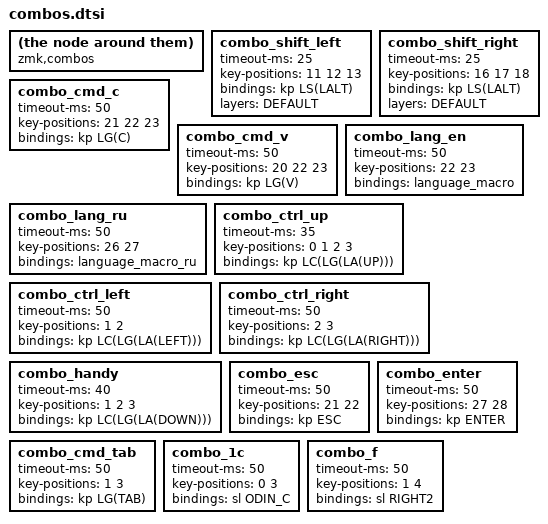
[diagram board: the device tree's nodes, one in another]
/*                KEY POSITIONS

╭────────────────────╮ ╭────────────────────╮
│  0   1   2   3   4 │ │  5   6   7   8   9 │
│ 10  11  12  13  14 │ │ 15  16  17  18  19 │
│ 20  21  22  23  24 │ │ 25  26  27  28  29 │
╰────────╮30  31  32 │ │ 33  34  35 ╭───────╯
         ╰───────────╯ ╰────────────╯       */

          
compatible = "zmk,combos";

// Shift
combo_shift_left { timeout-ms = <25>; key-positions = <11 13>; bindings = <&kp LSHIFT>; layers = <DEFAULT>; };
combo_shift_right { timeout-ms = <25>; key-positions = <16 18>; bindings = <&kp RSHIFT>; layers = <DEFAULT>; };
// Alt
combo_shift_left { timeout-ms = <25>; key-positions = <11 12>; bindings = <&kp LALT>; layers = <DEFAULT>; };
combo_shift_right { timeout-ms = <25>; key-positions = <17 18>; bindings = <&kp LALT>; layers = <DEFAULT>; };
// Alt+Shift
combo_shift_left { timeout-ms = <25>; key-positions = <11 12 13>; bindings = <&kp LS(LALT)>; layers = <DEFAULT>; };
combo_shift_right { timeout-ms = <25>; key-positions = <16 17 18>; bindings = <&kp LS(LALT)>; layers = <DEFAULT>; };

// Copy paste
combo_cmd_c { timeout-ms = <50>; key-positions = <21 22 23>; bindings = <&kp LG(C)>; };
// combo_cmd_x { timeout-ms = <50>; key-positions = <21 22>; bindings = <&kp LG(X)>; };
combo_cmd_v { timeout-ms = <50>; key-positions = <20 22 23>; bindings = <&kp LG(V)>; };

// Change language
combo_lang_en { timeout-ms = <50>; key-positions = <22 23>; bindings = <&language_macro>; };
combo_lang_ru { timeout-ms = <50>; key-positions = <26 27>; bindings = <&language_macro_ru>; };

// Mac Os navigation
combo_ctrl_up { timeout-ms = <35>; key-positions = <0 1 2 3>; bindings = <&kp LC(LG(LA(UP)))>; };
combo_ctrl_left { timeout-ms = <50>; key-positions = <1 2>; bindings = <&kp LC(LG(LA(LEFT)))>; };
combo_ctrl_right { timeout-ms = <50>; key-positions = <2 3>; bindings = <&kp LC(LG(LA(RIGHT)))>; };

// Handy push to talk
combo_handy { timeout-ms = <40>; key-positions = <1 2 3>; bindings = <&kp LC(LG(LA(DOWN)))>; };

// Esc and Enter
combo_esc { timeout-ms = <50>; key-positions = <21 22>; bindings = <&kp ESC>; };
combo_enter { timeout-ms = <50>; key-positions = <27 28>; bindings = <&kp ENTER>; };

// Command + tab
combo_cmd_tab { timeout-ms = <50>; key-positions = <1 3>; bindings = <&kp LG(TAB)>; };

// 1c momentary layer
combo_1c { timeout-ms = <50>; key-positions = <0 3>; bindings = <&sl ODIN_C>; };

// F_LAYER momentary layer
combo_f { timeout-ms = <50>; key-positions = <1 4>; bindings = <&sl RIGHT2>; };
